# STM32H73x register map
File version: 1.3
CPU: CM7 r0p1, little endian, MPU, FPU, 4 interrupt priority bits
Registers are 32-bit, read-write, reset 0x0 unless marked. A register's access mark holds for its fields unless they carry their own. Offsets are from the block's base; [hi:lo] are bit positions; {n}, {i} and the like mark numbered series; 'fields as' and 'values as' point back to an identical list.

## FPU_CPACR — Floating point unit CPACR
Base 0xE000ED88
0x00 CPACR — Coprocessor access control register
  [23:20] CP

## HSEM
Base 0x58026400
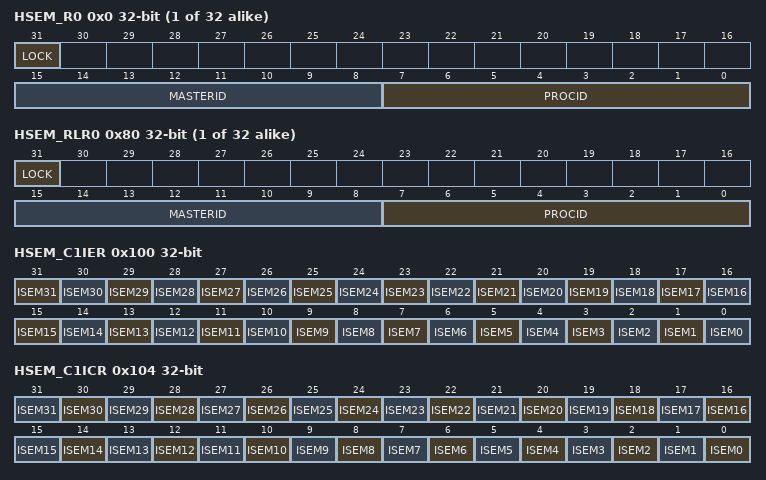
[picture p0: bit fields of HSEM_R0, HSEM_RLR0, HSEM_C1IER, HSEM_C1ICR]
{0x0+4i} HSEM_R{i} (i=0..31) — HSEM register HSEM_R0 HSEM_R31
  [31] LOCK — Lock indication
  [15:8] MASTERID — Semaphore MasterID
  [7:0] PROCID — Semaphore ProcessID
{0x80+4i} HSEM_RLR{i} ro (i=0..31) — HSEM Read lock register
  fields as HSEM_R0
0x100 HSEM_C1IER — HSEM Interrupt enable register
  [31] ISEM31 — Interrupt(N) semaphore n enable bit.
  [n] ISEM{n} (n=0..30) — Interrupt semaphore n enable bit
0x104 HSEM_C1ICR ro — HSEM Interrupt clear register
  [n] ISEM{n} (n=0..31) — Interrupt(N) semaphore n clear bit
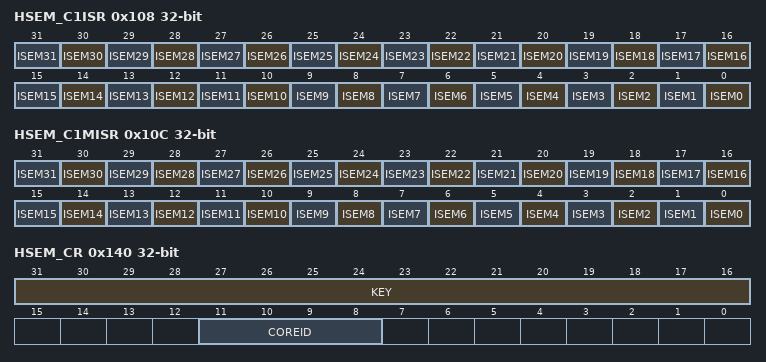
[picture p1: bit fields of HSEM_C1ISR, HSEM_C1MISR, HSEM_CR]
0x108 HSEM_C1ISR ro — HSEM Interrupt status register
  [n] ISEM{n} (n=0..31) — Interrupt(N) semaphore n status bit before enable (mask)
0x10C HSEM_C1MISR ro — HSEM Masked interrupt status register
  [n] ISEM{n} (n=0..31) — masked interrupt(N) semaphore n status bit after enable (mask)
0x140 HSEM_CR — HSEM Clear register
  [31:16] KEY — Semaphore clear Key
  [11:8] COREID — MasterID of semaphores to be cleared
0x144 HSEM_KEYR — HSEM Interrupt clear register
  [31:16] KEY — Semaphore Clear Key

## LPTIM1 — Low power timer
Base 0x40002400
Same registers: LPTIM2 0x58002400
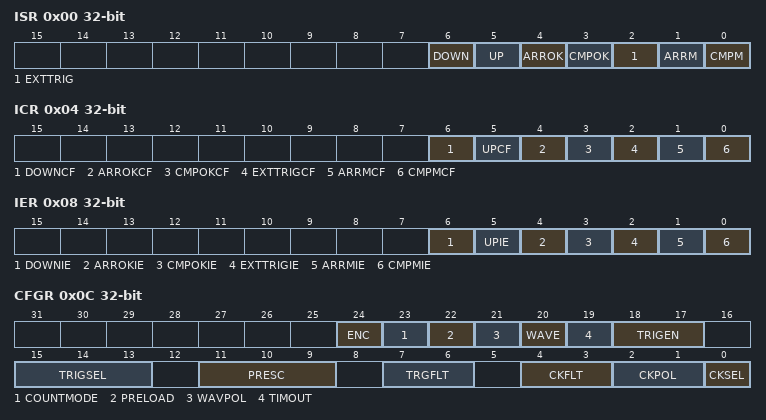
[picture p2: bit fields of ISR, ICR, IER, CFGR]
0x00 ISR ro — Interrupt and Status Register
  [6] DOWN — Counter direction change up to down
  [5] UP — Counter direction change down to up
  [4] ARROK — Autoreload register update OK
  [3] CMPOK — Compare register update OK
  [2] EXTTRIG — External trigger edge event
  [1] ARRM — Autoreload match
  [0] CMPM — Compare match
0x04 ICR wo — Interrupt Clear Register
  [6] DOWNCF — Direction change to down Clear Flag
  [5] UPCF — Direction change to UP Clear Flag
  [4] ARROKCF — Autoreload register update OK Clear Flag
  [3] CMPOKCF — Compare register update OK Clear Flag
  [2] EXTTRIGCF — External trigger valid edge Clear Flag
  [1] ARRMCF — Autoreload match Clear Flag
  [0] CMPMCF — compare match Clear Flag
0x08 IER — Interrupt Enable Register
  [6] DOWNIE — Direction change to down Interrupt Enable
  [5] UPIE — Direction change to UP Interrupt Enable
  [4] ARROKIE — Autoreload register update OK Interrupt Enable
  [3] CMPOKIE — Compare register update OK Interrupt Enable
  [2] EXTTRIGIE — External trigger valid edge Interrupt Enable
  [1] ARRMIE — Autoreload match Interrupt Enable
  [0] CMPMIE — Compare match Interrupt Enable
0x0C CFGR — Configuration Register
  [24] ENC — Encoder mode enable
  [23] COUNTMODE — counter mode enabled
  [22] PRELOAD — Registers update mode
  [21] WAVPOL — Waveform shape polarity
  [20] WAVE — Waveform shape
  [19] TIMOUT — Timeout enable
  [18:17] TRIGEN — Trigger enable and polarity
  [15:13] TRIGSEL — Trigger selector
  [11:9] PRESC — Clock prescaler
  [7:6] TRGFLT — Configurable digital filter for trigger
  [4:3] CKFLT — Configurable digital filter for external clock
  [2:1] CKPOL — Clock Polarity
  [0] CKSEL — Clock selector
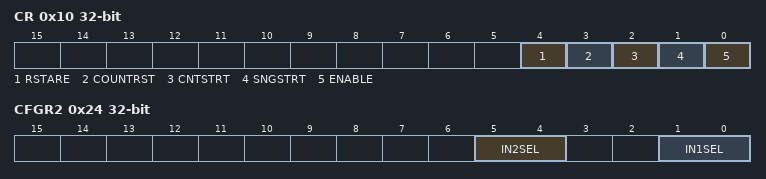
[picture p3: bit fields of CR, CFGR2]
0x10 CR — Control Register
  [4] RSTARE — Reset after read enable
  [3] COUNTRST — Counter reset
  [2] CNTSTRT — Timer start in continuous mode
  [1] SNGSTRT — LPTIM start in single mode
  [0] ENABLE — LPTIM Enable
0x14 CMP — Compare Register
  [15:0] CMP — Compare value
0x18 ARR reset 0x1 — Autoreload Register
  [15:0] ARR — Auto reload value
0x1C CNT ro — Counter Register
  [15:0] CNT — Counter value
0x24 CFGR2 — LPTIM configuration register 2
  [5:4] IN2SEL — LPTIM Input 2 selection
  [1:0] IN1SEL — LPTIM Input 1 selection

## LPTIM3 — Low power timer
Base 0x58002800
Same registers: LPTIM4 0x58002C00, LPTIM5 0x58003000
Registers as LPTIM1; these are added or differ:
0x24 CFGR2 — LPTIM configuration register 2
  [1:0] IN1SEL — LPTIM Input 1 selection
